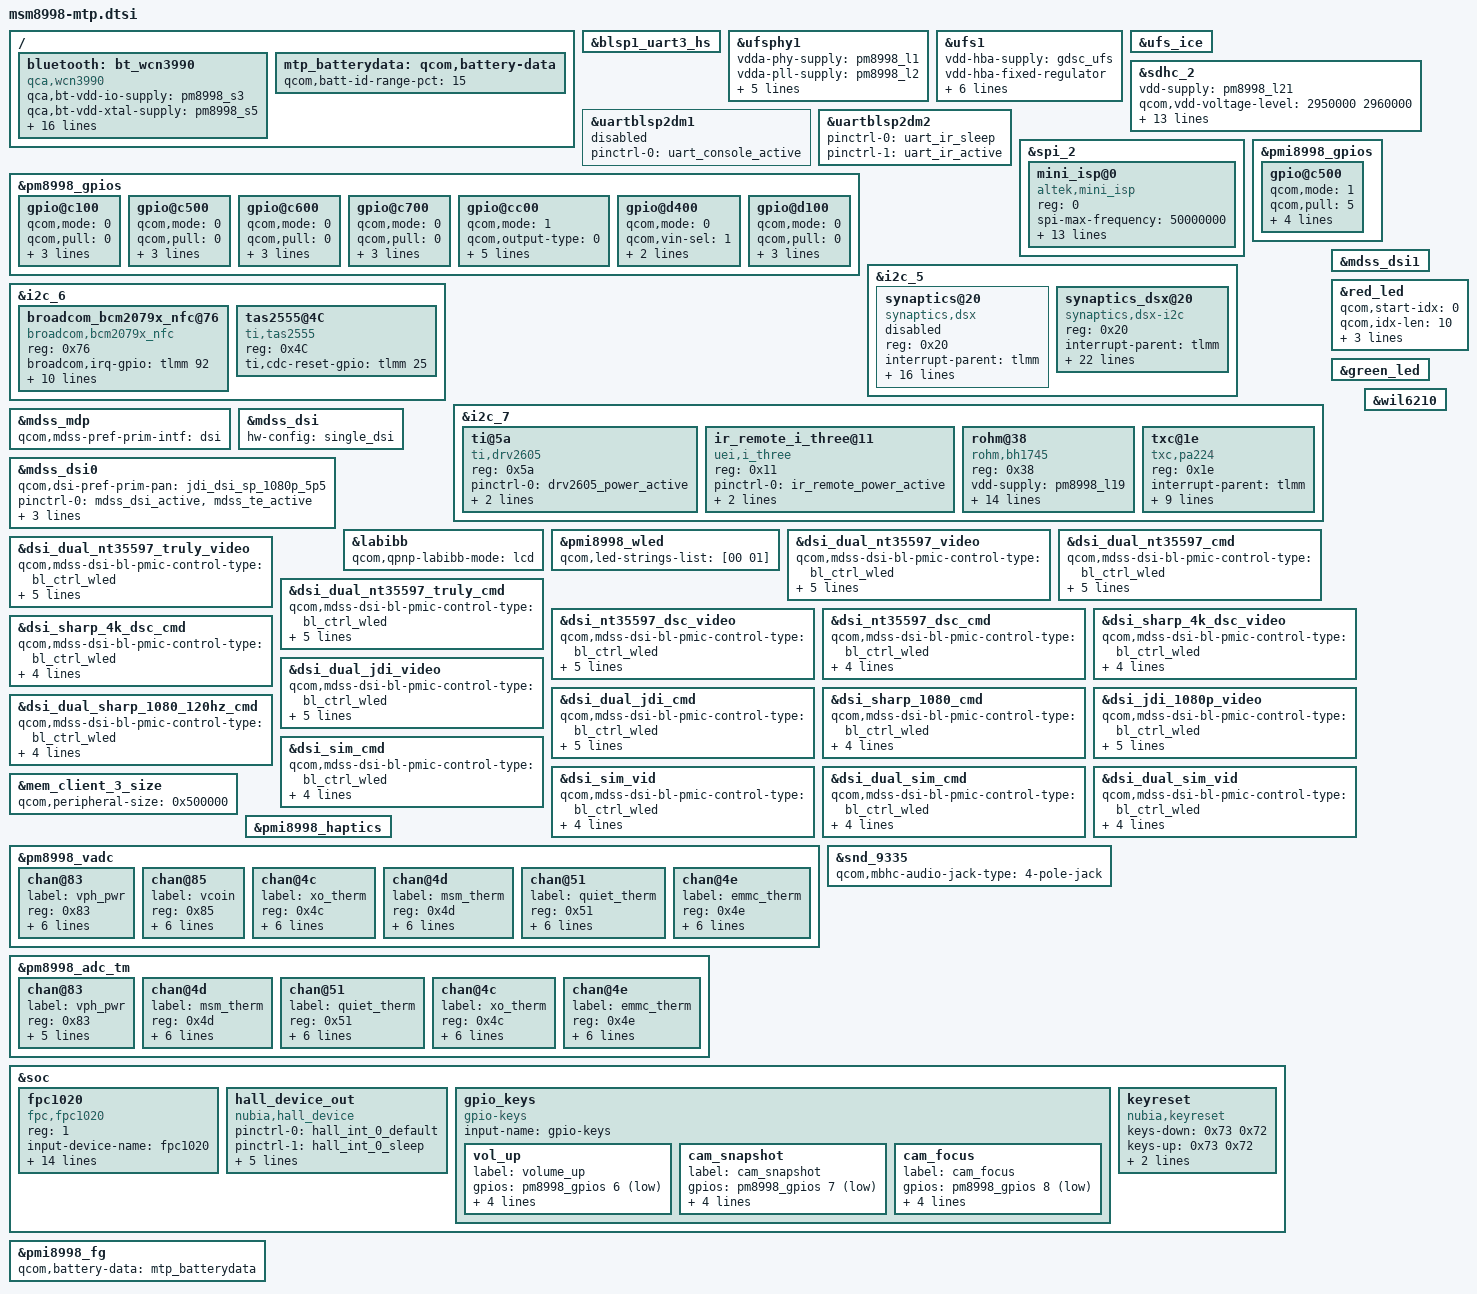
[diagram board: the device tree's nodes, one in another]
/* Copyright (c) 2016-2017, The Linux Foundation. All rights reserved.
 *
 * This program is free software; you can redistribute it and/or modify
 * it under the terms of the GNU General Public License version 2 and
 * only version 2 as published by the Free Software Foundation.
 *
 * This program is distributed in the hope that it will be useful,
 * but WITHOUT ANY WARRANTY; without even the implied warranty of
 * MERCHANTABILITY or FITNESS FOR A PARTICULAR PURPOSE.  See the
 * GNU General Public License for more details.
 */

#include <dt-bindings/interrupt-controller/irq.h>
#include "msm8998-pinctrl.dtsi"
#include "msm8998-camera-sensor-mtp.dtsi"

/ {
	bluetooth: bt_wcn3990 {
		compatible = "qca,wcn3990";
		qca,bt-vdd-io-supply = <&pm8998_s3>;
		qca,bt-vdd-xtal-supply = <&pm8998_s5>;
		qca,bt-vdd-core-supply = <&pm8998_l7>;
		qca,bt-vdd-pa-supply = <&pm8998_l17>;
		qca,bt-vdd-ldo-supply = <&pm8998_l25>;
		qca,bt-chip-pwd-supply = <&pmi8998_bob_pin1>;
		clocks = <&clock_gcc clk_rf_clk2_pin>;
		clock-names = "rf_clk2";

		qca,bt-vdd-io-voltage-level = <1352000 1352000>;
		qca,bt-vdd-xtal-voltage-level = <2040000 2040000>;
		qca,bt-vdd-core-voltage-level = <1800000 1800000>;
		qca,bt-vdd-pa-voltage-level = <1304000 1304000>;
		qca,bt-vdd-ldo-voltage-level = <3312000 3312000>;
		qca,bt-chip-pwd-voltage-level = <3600000 3600000>;

		qca,bt-vdd-io-current-level = <1>; /* LPM/PFM */
		qca,bt-vdd-xtal-current-level = <1>; /* LPM/PFM */
		qca,bt-vdd-core-current-level = <1>; /* LPM/PFM */
		qca,bt-vdd-pa-current-level = <1>; /* LPM/PFM */
		qca,bt-vdd-ldo-current-level = <1>; /* LPM/PFM */
	};
};

&blsp1_uart3_hs {
	status = "ok";
};

&ufsphy1 {
	vdda-phy-supply = <&pm8998_l1>;
	vdda-pll-supply = <&pm8998_l2>;
	vddp-ref-clk-supply = <&pm8998_l26>;
	vdda-phy-max-microamp = <51400>;
	vdda-pll-max-microamp = <14600>;
	vddp-ref-clk-max-microamp = <100>;
	vddp-ref-clk-always-on;
	status = "ok";
};

&ufs1 {
	vdd-hba-supply = <&gdsc_ufs>;
	vdd-hba-fixed-regulator;
	vcc-supply = <&pm8998_l20>;
	vccq-supply = <&pm8998_l26>;
	vccq2-supply = <&pm8998_s4>;
	vcc-max-microamp = <750000>;
	vccq-max-microamp = <560000>;
	vccq2-max-microamp = <750000>;
	status = "ok";
};

&ufs_ice {
	status = "ok";
};

&sdhc_2 {
	vdd-supply = <&pm8998_l21>;
	qcom,vdd-voltage-level = <2950000 2960000>;
	qcom,vdd-current-level = <200 800000>;

	vdd-io-supply = <&pm8998_l13>;
	qcom,vdd-io-voltage-level = <1808000 2960000>;
	qcom,vdd-io-current-level = <200 22000>;

	pinctrl-names = "active", "sleep";
	pinctrl-0 = <&sdc2_clk_on  &sdc2_cmd_on &sdc2_data_on &sdc2_cd_on>;
	pinctrl-1 = <&sdc2_clk_off &sdc2_cmd_off &sdc2_data_off &sdc2_cd_off>;

	qcom,clk-rates = <400000 20000000 25000000
				50000000 100000000 200000000>;
	qcom,bus-speed-mode = "SDR12", "SDR25", "SDR50", "DDR50", "SDR104";

	cd-gpios = <&tlmm 95 0x1>;

	status = "ok";
};

&uartblsp2dm1 {
	status = "disabled";
	pinctrl-names = "default";
	pinctrl-0 = <&uart_console_active>;
};

// Nubia add start
&uartblsp2dm2 {
	status = "ok";
	pinctrl-names = "sleep", "default";
	pinctrl-0 = <&uart_ir_sleep>;
	pinctrl-1 = <&uart_ir_active>;
};
// Nubia add end

&pm8998_gpios {
	/* GPIO 2 for Home Key */
	gpio@c100 {
		status = "okay";
		qcom,mode = <0>;
		qcom,pull = <0>;
		qcom,vin-sel = <0>;
		qcom,src-sel = <0>;
		qcom,out-strength = <1>;
	};

	/* GPIO 6 for Vol+ Key */
	gpio@c500 {
		status = "okay";
		qcom,mode = <0>;
		qcom,pull = <0>;
		qcom,vin-sel = <0>;
		qcom,src-sel = <0>;
		qcom,out-strength = <1>;
	};

	/* GPIO 7 for Snapshot Key */
	gpio@c600 {
		status = "okay";
		qcom,mode = <0>;
		qcom,pull = <0>;
		qcom,vin-sel = <0>;
		qcom,src-sel = <0>;
		qcom,out-strength = <1>;
	};

	/* GPIO 8 for Focus Key */
	gpio@c700 {
		status = "okay";
		qcom,mode = <0>;
		qcom,pull = <0>;
		qcom,vin-sel = <0>;
		qcom,src-sel = <0>;
		qcom,out-strength = <1>;
	};
	/* nubai add GPIO 12 for hw version */
	/*
	gpio@cb00 { // GPIO 12
		status = "okay";
		qcom,mode = <0>;
		qcom,pull = <0>;
		qcom,vin-sel = <0>;
		qcom,src-sel = <0>;
		qcom,out-strength = <1>;
	};
	*/
	gpio@cc00 { /* GPIO 13 */
		qcom,mode = <1>;
		qcom,output-type = <0>;
		qcom,pull = <5>;
		qcom,vin-sel = <0>;
		qcom,out-strength = <1>;
		qcom,src-sel = <3>;
		qcom,master-en = <1>;
		status = "okay";
	};

	/* GPIO 21 (NFC_CLK_REQ) */
	gpio@d400 {
		qcom,mode = <0>;
		qcom,vin-sel = <1>;
		qcom,src-sel = <0>;
		qcom,master-en = <1>;
		status = "okay";
	};

	/* GPIO 18 SMB138X */
	gpio@d100 {
		qcom,mode = <0>;
		qcom,pull = <0>;
		qcom,vin-sel = <0>;
		qcom,src-sel = <0>;
		qcom,master-en = <1>;
		status = "okay";
	};
};

//ZTEMT: fengxun added for AL3200 ---start
&spi_2 {
	status = "ok";
	mini_isp@0 {
		compatible = "altek,mini_isp";
		reg = <0>;
		spi-max-frequency = <50000000>;
		interrupt-parent = <&tlmm>;
		interrupts = <7 0x00>;
		pinctrl-names = "pmx_ts_active","pmx_ts_suspend";
		pinctrl-0 = <&al3200_gpio_int_active &al3200_gpio_active>;
		pinctrl-1 = <&al3200_gpio_int_sleep &al3200_gpio_sleep>;
		reset-gpios = <&tlmm 6 0x00>;
		irq-gpios = <&tlmm 7 0x00>;
		vcc1-gpios = <&tlmm 77 0x00>;
		vcc2-gpios = <&tlmm 115 0x00>;
		vcc3-gpios = <&tlmm 21 0x00>;
		clocks = <&clock_gcc clk_div_clk2>;
		clock-names = "al3200_clk";
		qcom,clock-rates = <19200000>;
		status = "ok";
	};
};
//ZTEMT: fengxun added for AL3200 ---end

&pmi8998_gpios {
	/* GPIO 6 for the internal QNOVO discharge FET control signal */
	gpio@c500 {
		status = "okay";
		qcom,mode = <1>;
		qcom,pull = <5>;
		qcom,vin-sel = <0>;
		qcom,src-sel = <2>;
		qcom,out-strength = <1>;
		qcom,master-en = <1>;
	};
};


&i2c_5 {
	status = "okay";
	synaptics@20 {
		compatible = "synaptics,dsx";
		status = "disabled";
		reg = <0x20>;
		interrupt-parent = <&tlmm>;
		interrupts = <125 0x2008>;
		vdd-supply = <&pm8998_l6>;
		avdd-supply = <&pm8998_l28>;
		synaptics,vdd-voltage = <1808000 1808000>;
		synaptics,avdd-voltage = <3008000 3008000>;
		synaptics,vdd-current = <40000>;
		synaptics,avdd-current = <20000>;
		pinctrl-names = "pmx_ts_active", "pmx_ts_suspend";
		pinctrl-0 = <&ts_active>;
		pinctrl-1 = <&ts_int_suspend &ts_reset_suspend>;
		synaptics,display-coords = <0 0 1439 2559>;
		synaptics,panel-coords = <0 0 1439 2559>;
		synaptics,reset-gpio = <&tlmm 89 0x00>;
		synaptics,irq-gpio = <&tlmm 125 0x2008>;
		synaptics,disable-gpios;
		synaptics,fw-name = "PR1702898-s3528t_60QHD_00400001.img";
	};

//nubia add touch start
	synaptics_dsx@20 {
		compatible = "synaptics,dsx-i2c";
		reg = <0x20>;
		interrupt-parent = <&tlmm>;
		interrupts = <125 0x2008>;
		vdd_lcd-supply = <&pm8998_l14>;
		vdd_ana-supply = <&pm8998_l28>;
		vcc_i2c-supply = <&pm8998_l6>;
		synaptics,tp-recovery-enable = <1>;
		synaptics,lcd-reg-name = "vdd_lcd";
		synaptics,pwr-reg-name = "vdd_ana";
		synaptics,bus-reg-name = "vcc_i2c";
		synaptics,irq-gpio = <&tlmm 125 0x2008>;
		synaptics,irq-on-state = <0>;
		synaptics,irq-flags = <0x2008>; /* IRQF_ONESHOT | IRQF_TRIGGER_LOW */
		synaptics,power-delay-ms = <20>;
		//synaptics,power-gpio = <&msm_gpio 69 0x0>;
		//synaptics,power-on-state = <1>;
		synaptics,reset-gpio = <&tlmm 89 0x0>;
		synaptics,reset-on-state = <0>;
		synaptics,reset-active-ms = <20>;
		synaptics,reset-delay-ms = <20>;
		//synaptics,lcd-reset-gpio = <&tlmm 94 0x0>;
		synaptics,cap-button-codes = <172 139 158>;
		synaptics,ub-i2c-addr = <0x20>;
		pinctrl-names = "synaptics_pin_active", "synaptics_pin_suspend";
		pinctrl-0 = <&synaptics_int_active &synaptics_reset_active>;
		pinctrl-1 = <&synaptics_int_suspend &synaptics_reset_suspend>;
	};
//nubia add touch end
};

&i2c_6 { /* BLSP1 QUP6 (NFC) */
	status = "okay";
	/*nq@28 {
		compatible = "qcom,nq-nci";
		reg = <0x28>;
		qcom,nq-irq = <&tlmm 92 0x00>;
		qcom,nq-ven = <&tlmm 12 0x00>;
		qcom,nq-firm = <&tlmm 93 0x00>;
		qcom,nq-clkreq = <&pm8998_gpios 21 0x00>;
		qcom,nq-esepwr = <&tlmm 116 0x00>;
		interrupt-parent = <&tlmm>;
		qcom,clk-src = "BBCLK3";
		interrupts = <92 0>;
		interrupt-names = "nfc_irq";
		pinctrl-names = "nfc_active", "nfc_suspend";
		pinctrl-0 = <&nfc_int_active &nfc_enable_active>;
		pinctrl-1 = <&nfc_int_suspend &nfc_enable_suspend>;
		clocks = <&clock_gcc clk_ln_bb_clk3_pin>;
		clock-names = "ref_clk";
	};*/

	// add by slv for nfc-bcm20797
	broadcom_bcm2079x_nfc@76{
		compatible = "broadcom,bcm2079x_nfc";
		reg = <0x76>;
		broadcom,irq-gpio = <&tlmm 92 0x00>;
		broadcom,en-gpio = <&tlmm 12 0x00>;
		broadcom,wake-gpio = <&tlmm 76 0x00>;
		interrupt-parent = <&tlmm>;
		interrupts = <92 0>;
		interrupt-names = "BRCM_NFC_INT";
		pinctrl-names = "bcm2079x_pin_active","bcm2079x_pin_suspend";
		pinctrl-0 = <&bcm2079x_int_active &bcm2079x_en_active &bcm2079x_ctl_active>;
		pinctrl-1 = <&bcm2079x_int_suspend &bcm2079x_en_suspend &bcm2079x_ctl_suspend>;
		//status = "ok";
		broadcom,clk-gpio = <&pm8998_gpios 21 0x00>;
		clocks = <&clock_gcc clk_ln_bb_clk3_pin>;
		clock-names = "ref_clk";
	};

	  tas2555@4C {
               compatible = "ti,tas2555";
               reg = <0x4C>;
               ti,cdc-reset-gpio = <&tlmm 25 0x00>;
     };
};

&i2c_7 {
	status = "okay";
	// Nubia add start
	ti@5a{
		compatible = "ti,drv2605";
		reg = <0x5a>;
		pinctrl-names = "active","suspend";
		pinctrl-0 = <&drv2605_power_active>;
		pinctrl-1 = <&drv2605_power_suspend>;
		ti,enable-gpio=<&tlmm 95 0x0>;
	};
	ir_remote_i_three@11 {
		status = "okay";
		reg = <0x11>;
		compatible = "uei,i_three";
		//vdd-supply = <&pm8994_l17>;
		pinctrl-names = "active", "suspend";
		pinctrl-0 = <&ir_remote_power_active>;
		pinctrl-1 = <&ir_remote_power_suspend>;
		ir_remote,enable-gpio = <&tlmm 39 0x0>;
	};
	rohm@38 {
		compatible = "rohm,bh1745";
		reg = <0x38>;
		vdd-supply = <&pm8998_l19>;
		vio-supply = <&pm8998_s4>;
		bh1745,tp_moudle_count = <3>;
		/*[module_id] [golden judge] r[0] r[1] g[0] g[1] b[0] b[1]*/
		bh1745,cal_data0 = "0","162","500","270","1832","1648","0","0",
		/*[white judge] r[0] r[1] g[0] g[1] b[0] b[1]*/
		"184","166","111","531","460","0","0",
		/*[balck judge] r[0] r[1] g[0] g[1] b[0] b[1]*/
		"313","1151","1532","5957","8584","0","0",
		/*[blue judge] r[0] r[1] g[0] g[1] b[0] b[1]*/
		"265","547","351","2337","1923","0","0";
		/*[module_id] [golden judge] r[0] r[1] g[0] g[1] b[0] b[1]*/
		bh1745,cal_data1 = "1","242","1565","932","9035","8607","0","0",
		/*[white judge] r[0] r[1] g[0] g[1] b[0] b[1]*/
		"189","146","88","598","533","0","0",
		/*[balck judge] r[0] r[1] g[0] g[1] b[0] b[1]*/
		"1040","1911","310","11509","9976","0","0",
		/*[blue judge] r[0] r[1] g[0] g[1] b[0] b[1]*/
		"265","547","351","2337","1923","0","0";
		/*[module_id] [golden judge] r[0] r[1] g[0] g[1] b[0] b[1]*/
		bh1745,cal_data2 = "2","199","488","274","2283","2068","0","0",
		/*[white judge] r[0] r[1] g[0] g[1] b[0] b[1]*/
		"194","216","113","886","821","0","0",
		/*[balck judge] r[0] r[1] g[0] g[1] b[0] b[1]*/
		"396","2301","547","13243","12687","0","0",
		/*[blue judge] r[0] r[1] g[0] g[1] b[0] b[1]*/
		"265","547","351","2337","1923","0","0";
	};
	txc@1e {
		compatible = "txc,pa224";
		reg = <0x1e>;
		interrupt-parent = <&tlmm>;
		interrupts = <62 0x2>;
		vdd-supply = <&pm8998_l19>;
		vio-supply = <&pm8998_s4>;
		txc,irq-gpio = <&tlmm 62 0x2002>;
		txc,ps_threshold_low = <30>;
		txc,ps_threshold_high = <120>;
		pinctrl-names = "pa224_default","pa224_sleep";
		pinctrl-0 = <&pa224_default>;
		pinctrl-1 =<&pa224_sleep>;
		txc,vdd-always-on = <1>;
	};
	// Nubia add end
};
/*
//ZTEMT:fengxun modify for camera AL3200
&mdss_hdmi_tx {
	pinctrl-names = "hdmi_hpd_active", "hdmi_ddc_active", "hdmi_cec_active",
				"hdmi_active", "hdmi_sleep";
	pinctrl-0 = <&mdss_hdmi_5v_active  &mdss_hdmi_hpd_active
			&mdss_hdmi_ddc_suspend &mdss_hdmi_cec_suspend>;
	pinctrl-1 = <&mdss_hdmi_5v_active &mdss_hdmi_hpd_active
			&mdss_hdmi_ddc_active &mdss_hdmi_cec_suspend>;
	pinctrl-2 = <&mdss_hdmi_5v_active &mdss_hdmi_hpd_active
			&mdss_hdmi_cec_active &mdss_hdmi_ddc_suspend>;
	pinctrl-3 = <&mdss_hdmi_5v_active &mdss_hdmi_hpd_active
			&mdss_hdmi_ddc_active &mdss_hdmi_cec_active>;
	pinctrl-4 = <&mdss_hdmi_5v_suspend &mdss_hdmi_hpd_suspend
			&mdss_hdmi_ddc_suspend &mdss_hdmi_cec_suspend>;
};

&mdss_dp_ctrl {
	pinctrl-names = "mdss_dp_active", "mdss_dp_sleep";
	pinctrl-0 = <&mdss_dp_aux_active &mdss_dp_usbplug_cc_active>;
	pinctrl-1 = <&mdss_dp_aux_suspend &mdss_dp_usbplug_cc_suspend>;
	qcom,aux-en-gpio = <&tlmm 77 0>;
	qcom,aux-sel-gpio = <&tlmm 78 0>;
	qcom,usbplug-cc-gpio = <&tlmm 38 0>;
};
*/
&mdss_mdp {
	qcom,mdss-pref-prim-intf = "dsi";
};

&mdss_dsi {
	hw-config = "single_dsi";
};

&mdss_dsi0 {
	qcom,dsi-pref-prim-pan = <&jdi_dsi_sp_1080p_5p5>;
	pinctrl-names = "mdss_default", "mdss_sleep";
	pinctrl-0 = <&mdss_dsi_active &mdss_te_active>;
	pinctrl-1 = <&mdss_dsi_suspend &mdss_te_suspend>;
	qcom,platform-reset-gpio = <&tlmm 94 0>;
	qcom,platform-te-gpio = <&tlmm 10 0>;
};

&mdss_dsi1 {
};

&labibb {
	status = "ok";
	qcom,qpnp-labibb-mode = "lcd";
};

&pmi8998_wled {
	qcom,led-strings-list = [00 01];
};

&red_led {
	/delete-property/ linux,default-trigger;
	qcom,start-idx = <0>;
	qcom,idx-len = <10>;
	qcom,duty-pcts = [00 19 32 4b 64
			64 4b 32 19 00];
	qcom,use-blink;
};

&green_led {
	/delete-property/ linux,default-trigger;
};

&dsi_dual_nt35597_video {
	qcom,mdss-dsi-bl-pmic-control-type = "bl_ctrl_wled";
	qcom,mdss-dsi-bl-min-level = <1>;
	qcom,mdss-dsi-bl-max-level = <4095>;
	qcom,mdss-dsi-mode-sel-gpio-state = "dual_port";
	qcom,panel-supply-entries = <&dsi_panel_pwr_supply>;
};

&dsi_dual_nt35597_cmd {
	qcom,mdss-dsi-bl-pmic-control-type = "bl_ctrl_wled";
	qcom,mdss-dsi-bl-min-level = <1>;
	qcom,mdss-dsi-bl-max-level = <4095>;
	qcom,mdss-dsi-mode-sel-gpio-state = "dual_port";
	qcom,panel-supply-entries = <&dsi_panel_pwr_supply>;
};

&dsi_dual_nt35597_truly_video {
	qcom,mdss-dsi-bl-pmic-control-type = "bl_ctrl_wled";
	qcom,mdss-dsi-bl-min-level = <1>;
	qcom,mdss-dsi-bl-max-level = <4095>;
	qcom,mdss-dsi-mode-sel-gpio-state = "dual_port";
	qcom,panel-supply-entries = <&dsi_panel_pwr_supply>;
};

&dsi_dual_nt35597_truly_cmd {
	qcom,mdss-dsi-bl-pmic-control-type = "bl_ctrl_wled";
	qcom,mdss-dsi-bl-min-level = <1>;
	qcom,mdss-dsi-bl-max-level = <4095>;
	qcom,mdss-dsi-mode-sel-gpio-state = "dual_port";
	qcom,panel-supply-entries = <&dsi_panel_pwr_supply>;
};

&dsi_nt35597_dsc_video {
	qcom,mdss-dsi-bl-pmic-control-type = "bl_ctrl_wled";
	qcom,mdss-dsi-bl-min-level = <1>;
	qcom,mdss-dsi-bl-max-level = <4095>;
	qcom,mdss-dsi-mode-sel-gpio-state = "single_port";
	qcom,panel-supply-entries = <&dsi_panel_pwr_supply>;
};

&dsi_nt35597_dsc_cmd {
	qcom,mdss-dsi-bl-pmic-control-type = "bl_ctrl_wled";
	qcom,mdss-dsi-bl-min-level = <1>;
	qcom,mdss-dsi-bl-max-level = <4095>;
	qcom,panel-supply-entries = <&dsi_panel_pwr_supply>;
};

&dsi_sharp_4k_dsc_video {
	qcom,mdss-dsi-bl-pmic-control-type = "bl_ctrl_wled";
	qcom,mdss-dsi-bl-min-level = <1>;
	qcom,mdss-dsi-bl-max-level = <4095>;
	qcom,panel-supply-entries = <&dsi_panel_pwr_supply>;
};

&dsi_sharp_4k_dsc_cmd {
	qcom,mdss-dsi-bl-pmic-control-type = "bl_ctrl_wled";
	qcom,mdss-dsi-bl-min-level = <1>;
	qcom,mdss-dsi-bl-max-level = <4095>;
	qcom,panel-supply-entries = <&dsi_panel_pwr_supply>;
};

&dsi_dual_jdi_video {
	qcom,mdss-dsi-bl-pmic-control-type = "bl_ctrl_wled";
	qcom,mdss-dsi-bl-min-level = <1>;
	qcom,mdss-dsi-bl-max-level = <4095>;
	qcom,5v-boost-gpio = <&tlmm 51 0>;
	qcom,panel-supply-entries = <&dsi_panel_pwr_supply>;
};

&dsi_dual_jdi_cmd {
	qcom,mdss-dsi-bl-pmic-control-type = "bl_ctrl_wled";
	qcom,mdss-dsi-bl-min-level = <1>;
	qcom,mdss-dsi-bl-max-level = <4095>;
	qcom,5v-boost-gpio = <&tlmm 51 0>;
	qcom,panel-supply-entries = <&dsi_panel_pwr_supply>;
};

&dsi_sharp_1080_cmd {
	qcom,mdss-dsi-bl-pmic-control-type = "bl_ctrl_wled";
	qcom,mdss-dsi-bl-min-level = <1>;
	qcom,mdss-dsi-bl-max-level = <4095>;
	qcom,panel-supply-entries = <&dsi_panel_pwr_supply>;
};

&dsi_jdi_1080p_video {
	qcom,mdss-dsi-bl-pmic-control-type = "bl_ctrl_wled";
	qcom,mdss-dsi-bl-min-level = <1>;
	qcom,mdss-dsi-bl-max-level = <4095>;
	qcom,panel-supply-entries = <&dsi_panel_pwr_supply_no_labibb>;
	qcom,5v-boost-gpio = <&tlmm 51 0>;
};

&dsi_dual_sharp_1080_120hz_cmd {
	qcom,mdss-dsi-bl-pmic-control-type = "bl_ctrl_wled";
	qcom,mdss-dsi-bl-min-level = <1>;
	qcom,mdss-dsi-bl-max-level = <4095>;
	qcom,panel-supply-entries = <&dsi_panel_pwr_supply>;
};

&dsi_sim_cmd {
	qcom,mdss-dsi-bl-pmic-control-type = "bl_ctrl_wled";
	qcom,mdss-dsi-bl-min-level = <1>;
	qcom,mdss-dsi-bl-max-level = <4095>;
	qcom,panel-supply-entries = <&dsi_panel_pwr_supply>;
};

&dsi_sim_vid {
	qcom,mdss-dsi-bl-pmic-control-type = "bl_ctrl_wled";
	qcom,mdss-dsi-bl-min-level = <1>;
	qcom,mdss-dsi-bl-max-level = <4095>;
	qcom,panel-supply-entries = <&dsi_panel_pwr_supply>;
};

&dsi_dual_sim_cmd {
	qcom,mdss-dsi-bl-pmic-control-type = "bl_ctrl_wled";
	qcom,mdss-dsi-bl-min-level = <1>;
	qcom,mdss-dsi-bl-max-level = <4095>;
	qcom,panel-supply-entries = <&dsi_panel_pwr_supply>;
};

&dsi_dual_sim_vid {
	qcom,mdss-dsi-bl-pmic-control-type = "bl_ctrl_wled";
	qcom,mdss-dsi-bl-min-level = <1>;
	qcom,mdss-dsi-bl-max-level = <4095>;
	qcom,panel-supply-entries = <&dsi_panel_pwr_supply>;
};

&mem_client_3_size {
	qcom,peripheral-size = <0x500000>;
};

&pmi8998_haptics {
	status = "okay";
};

&pm8998_vadc {
	chan@83 {
		label = "vph_pwr";
		reg = <0x83>;
		qcom,decimation = <2>;
		qcom,pre-div-channel-scaling = <1>;
		qcom,calibration-type = "absolute";
		qcom,scale-function = <0>;
		qcom,hw-settle-time = <0>;
		qcom,fast-avg-setup = <0>;
	};

	chan@85 {
		label = "vcoin";
		reg = <0x85>;
		qcom,decimation = <2>;
		qcom,pre-div-channel-scaling = <1>;
		qcom,calibration-type = "absolute";
		qcom,scale-function = <0>;
		qcom,hw-settle-time = <0>;
		qcom,fast-avg-setup = <0>;
	};

	chan@4c {
		label = "xo_therm";
		reg = <0x4c>;
		qcom,decimation = <2>;
		qcom,pre-div-channel-scaling = <0>;
		qcom,calibration-type = "ratiometric";
		qcom,scale-function = <4>;
		qcom,hw-settle-time = <2>;
		qcom,fast-avg-setup = <0>;
	};

	chan@4d {
		label = "msm_therm";
		reg = <0x4d>;
		qcom,decimation = <2>;
		qcom,pre-div-channel-scaling = <0>;
		qcom,calibration-type = "ratiometric";
		qcom,scale-function = <2>;
		qcom,hw-settle-time = <2>;
		qcom,fast-avg-setup = <0>;
	};

	chan@51 {
		label = "quiet_therm";
		reg = <0x51>;
		qcom,decimation = <2>;
		qcom,pre-div-channel-scaling = <0>;
		qcom,calibration-type = "ratiometric";
		qcom,scale-function = <2>;
		qcom,hw-settle-time = <2>;
		qcom,fast-avg-setup = <0>;
	};

	chan@4e {
		label = "emmc_therm";
		reg = <0x4e>;
		qcom,decimation = <2>;
		qcom,pre-div-channel-scaling = <0>;
		qcom,calibration-type = "ratiometric";
		qcom,scale-function = <2>;
		qcom,hw-settle-time = <2>;
		qcom,fast-avg-setup = <0>;
	};
};

&pm8998_adc_tm {
	chan@83 {
		label = "vph_pwr";
		reg = <0x83>;
		qcom,pre-div-channel-scaling = <1>;
		qcom,calibration-type = "absolute";
		qcom,scale-function = <0>;
		qcom,hw-settle-time = <0>;
		qcom,btm-channel-number = <0x60>;
	};

	chan@4d {
		label = "msm_therm";
		reg = <0x4d>;
		qcom,pre-div-channel-scaling = <0>;
		qcom,calibration-type = "ratiometric";
		qcom,scale-function = <2>;
		qcom,hw-settle-time = <2>;
		qcom,btm-channel-number = <0x68>;
		qcom,thermal-node;
	};

	chan@51 {
		label = "quiet_therm";
		reg = <0x51>;
		qcom,pre-div-channel-scaling = <0>;
		qcom,calibration-type = "ratiometric";
		qcom,scale-function = <2>;
		qcom,hw-settle-time = <2>;
		qcom,btm-channel-number = <0x70>;
		qcom,thermal-node;
	};

	chan@4c {
		label = "xo_therm";
		reg = <0x4c>;
		qcom,pre-div-channel-scaling = <0>;
		qcom,calibration-type = "ratiometric";
		qcom,scale-function = <4>;
		qcom,hw-settle-time = <2>;
		qcom,btm-channel-number = <0x78>;
		qcom,thermal-node;
	};

	chan@4e {
		label = "emmc_therm";
		reg = <0x4e>;
		qcom,pre-div-channel-scaling = <0>;
		qcom,calibration-type = "ratiometric";
		qcom,scale-function = <2>;
		qcom,hw-settle-time = <2>;
		qcom,btm-channel-number = <0x80>;
		qcom,thermal-node;
	};
};

&wil6210 {
	status = "ok";
};

&snd_9335 {
	qcom,mbhc-audio-jack-type = "4-pole-jack";
};

&soc {
	// nubia add start
	// add fpc fingerprint as platform device
	fpc1020{
		status = "ok";
		reg = <1>;
		compatible = "fpc,fpc1020";
		input-device-name = "fpc1020";
		interrupt-parent = <&tlmm>;
		interrupts = <121 0>;
		fpc,reset-gpio = <&tlmm 85 0x00>;
		fpc,irq-gpio = <&tlmm 121 0x00>;
		fpc,enable-vdd-ldo = <&tlmm 79 0x00>;
		fpc,enable-vddio-ldo = <&tlmm 40 0x00>;
		pinctrl-names = "pmx_fp_active", "pmx_fp_suspend";
		pinctrl-0 = <&fp_drdy_active &fp_rst_active &fp_enable_active &fp_enable_vddio_active>;
		pinctrl-1 = <&fp_drdy_suspend &fp_rst_suspend &fp_enable_suspend &fp_enable_vddio_suspend>;

		spi-max-frequency = <4800000>;
		spi-qup-id = <1>;
		clock-names = "iface_clk", "core_clk";
		clocks = <&clock_gcc clk_gcc_blsp2_ahb_clk>,
			     <&clock_gcc clk_gcc_blsp2_qup6_spi_apps_clk>;
	};
	hall_device_out {
		compatible = "nubia,hall_device";
		status = "okay";
		pinctrl-names = "hall_default","hall_sleep";
		pinctrl-0 = <&hall_int_0_default >;
		pinctrl-1 = <&hall_int_0_sleep >;
		vdd-supply = <&pm8998_lvs2>;
		interrupt-parent = <&tlmm>;
		hall_device,hw_device_count = <2>;
		hall_device,irq-gpio-0 = <&tlmm 124 0x2002>;
		hall_device,irq-gpio-1 = <&tlmm 123 0x2002>;
	};
	// nubia add end
	gpio_keys {
		compatible = "gpio-keys";
		input-name = "gpio-keys";
		status = "okay";

		vol_up {
			label = "volume_up";
			gpios = <&pm8998_gpios 6 0x1>;
			linux,input-type = <1>;
			linux,code = <115>;
			gpio-key,wakeup;
			debounce-interval = <15>;
		};

		cam_snapshot {
			label = "cam_snapshot";
			gpios = <&pm8998_gpios 7 0x1>;
			linux,input-type = <1>;
			linux,code = <766>;
			gpio-key,wakeup;
			debounce-interval = <15>;
		};

		cam_focus {
			label = "cam_focus";
			gpios = <&pm8998_gpios 8 0x1>;
			linux,input-type = <1>;
			linux,code = <528>;
			gpio-key,wakeup;
			debounce-interval = <15>;
		};
	};

	keyreset {
		compatible = "nubia,keyreset";
		keys-down = <0x73 0x72>;
		keys-up = <0x73 0x72>;
		keyreset-need-panic;
		key_down_delay = <20>;
	};

};

/{
	mtp_batterydata: qcom,battery-data {
		qcom,batt-id-range-pct = <15>;
		#include "fg-gen3-batterydata-scud-3200mah.dtsi"
	};
};

&pmi8998_fg {
	qcom,battery-data = <&mtp_batterydata>;
};
